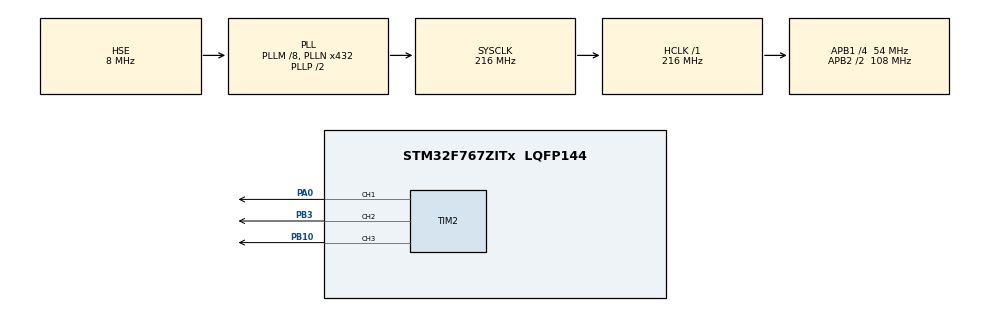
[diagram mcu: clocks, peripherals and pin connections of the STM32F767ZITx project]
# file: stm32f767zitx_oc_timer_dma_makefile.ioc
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Dma.Request0=TIM2_CH1
Dma.Request1=TIM2_CH2/CH4
Dma.Request2=TIM2_UP/CH3
Dma.TIM2_CH1.0.Direction=DMA_MEMORY_TO_PERIPH
Dma.TIM2_CH1.0.FIFOMode=DMA_FIFOMODE_ENABLE
Dma.TIM2_CH1.0.FIFOThreshold=DMA_FIFO_THRESHOLD_FULL
Dma.TIM2_CH1.0.Instance=DMA1_Stream5
Dma.TIM2_CH1.0.MemBurst=DMA_MBURST_SINGLE
Dma.TIM2_CH1.0.MemDataAlignment=DMA_MDATAALIGN_WORD
Dma.TIM2_CH1.0.MemInc=DMA_MINC_ENABLE
Dma.TIM2_CH1.0.Mode=DMA_CIRCULAR
Dma.TIM2_CH1.0.PeriphBurst=DMA_PBURST_SINGLE
Dma.TIM2_CH1.0.PeriphDataAlignment=DMA_PDATAALIGN_WORD
Dma.TIM2_CH1.0.PeriphInc=DMA_PINC_DISABLE
Dma.TIM2_CH1.0.Priority=DMA_PRIORITY_HIGH
Dma.TIM2_CH2/CH4.1.Direction=DMA_MEMORY_TO_PERIPH
Dma.TIM2_CH2/CH4.1.FIFOMode=DMA_FIFOMODE_ENABLE
Dma.TIM2_CH2/CH4.1.FIFOThreshold=DMA_FIFO_THRESHOLD_FULL
Dma.TIM2_CH2/CH4.1.Instance=DMA1_Stream6
Dma.TIM2_CH2/CH4.1.MemBurst=DMA_MBURST_SINGLE
Dma.TIM2_CH2/CH4.1.MemDataAlignment=DMA_MDATAALIGN_WORD
Dma.TIM2_CH2/CH4.1.MemInc=DMA_MINC_ENABLE
Dma.TIM2_CH2/CH4.1.Mode=DMA_CIRCULAR
Dma.TIM2_CH2/CH4.1.PeriphBurst=DMA_PBURST_SINGLE
Dma.TIM2_CH2/CH4.1.PeriphDataAlignment=DMA_PDATAALIGN_WORD
Dma.TIM2_CH2/CH4.1.PeriphInc=DMA_PINC_DISABLE
Dma.TIM2_CH2/CH4.1.Priority=DMA_PRIORITY_MEDIUM
Dma.TIM2_UP/CH3.2.Direction=DMA_MEMORY_TO_PERIPH
Dma.TIM2_UP/CH3.2.FIFOMode=DMA_FIFOMODE_ENABLE
Dma.TIM2_UP/CH3.2.FIFOThreshold=DMA_FIFO_THRESHOLD_FULL
Dma.TIM2_UP/CH3.2.Instance=DMA1_Stream1
Dma.TIM2_UP/CH3.2.MemBurst=DMA_MBURST_SINGLE
Dma.TIM2_UP/CH3.2.MemDataAlignment=DMA_MDATAALIGN_WORD
Dma.TIM2_UP/CH3.2.MemInc=DMA_MINC_ENABLE
Dma.TIM2_UP/CH3.2.Mode=DMA_CIRCULAR
Dma.TIM2_UP/CH3.2.PeriphBurst=DMA_PBURST_SINGLE
Dma.TIM2_UP/CH3.2.PeriphDataAlignment=DMA_PDATAALIGN_WORD
Dma.TIM2_UP/CH3.2.PeriphInc=DMA_PINC_DISABLE
Dma.TIM2_UP/CH3.2.Priority=DMA_PRIORITY_LOW
Mcu.Family=STM32F7
Mcu.Name=STM32F767ZITx
Mcu.Package=LQFP144
NVIC.DMA1_Stream1_IRQn=true\:0\:0\:false\:false\:true\:false\:true\:true
NVIC.DMA1_Stream5_IRQn=true\:0\:0\:false\:false\:true\:false\:true\:true
NVIC.DMA1_Stream6_IRQn=true\:0\:0\:false\:false\:true\:false\:true\:true
NVIC.PriorityGroup=NVIC_PRIORITYGROUP_4
PA0/WKUP.Signal=S_TIM2_CH1_ETR
PB10.Signal=S_TIM2_CH3
PB3.Signal=S_TIM2_CH2
PH0/OSC_IN.Mode=HSE-External-Clock-Source
PH0/OSC_IN.Signal=RCC_OSC_IN
PH1/OSC_OUT.Mode=HSE-External-Clock-Source
PH1/OSC_OUT.Signal=RCC_OSC_OUT
ProjectManager.HeapSize=0x200
ProjectManager.StackSize=0x400
ProjectManager.TargetToolchain=Makefile
RCC.48MHZClocksFreq_Value=24000000
RCC.AHBFreq_Value=216000000
RCC.APB1CLKDivider=RCC_HCLK_DIV4
RCC.APB1Freq_Value=54000000
RCC.APB1TimFreq_Value=108000000
RCC.APB2CLKDivider=RCC_HCLK_DIV2
RCC.APB2Freq_Value=108000000
RCC.APB2TimFreq_Value=216000000
RCC.CortexFreq_Value=216000000
RCC.HCLKFreq_Value=216000000
RCC.HSE_VALUE=8000000
RCC.HSI_VALUE=16000000
RCC.LSE_VALUE=32768
RCC.PLLM=8
RCC.PLLMUL=RCC_PLL_MUL9
RCC.PLLN=432
RCC.PLLSourceVirtual=RCC_PLLSOURCE_HSE
RCC.PRESCALERUSB=RCC_USBCLKSOURCE_PLL_DIV1_5
RCC.SYSCLKFreq_VALUE=216000000
RCC.SYSCLKSource=RCC_SYSCLKSOURCE_PLLCLK
RCC.SYSCLKSourceVirtual=RCC_SYSCLKSOURCE_PLLCLK
RCC.USBFreq_Value=216000000
RCC.VCOOutputFreq_Value=432000000
SH.S_TIM2_CH1_ETR.0=TIM2_CH1,Output Compare1 CH1
SH.S_TIM2_CH2.0=TIM2_CH2,Output Compare2 CH2
SH.S_TIM2_CH3.0=TIM2_CH3,Output Compare3 CH3
TIM2.Channel-Output\ Compare1\ CH1=TIM_CHANNEL_1
TIM2.Channel-Output\ Compare2\ CH2=TIM_CHANNEL_2
TIM2.Channel-Output\ Compare3\ CH3=TIM_CHANNEL_3
TIM2.OC1Preload=DISABLE
TIM2.OCMode_1=TIM_OCMODE_TOGGLE
TIM2.OCMode_2=TIM_OCMODE_TOGGLE
TIM2.OCMode_3=TIM_OCMODE_TOGGLE
VP_TIM2_VS_ClockSourceINT.Mode=Internal
board=NUCLEO-F767ZI

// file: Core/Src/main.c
/* USER CODE BEGIN Header */
/**
 ******************************************************************************
 * @file           : main.c
 * @brief          : Main program body
 ******************************************************************************
 * @attention
 *
 * Copyright (c) 2023 STMicroelectronics.
 * All rights reserved.
 *
 * This software is licensed under terms that can be found in the LICENSE file
 * in the root directory of this software component.
 * If no LICENSE file comes with this software, it is provided AS-IS.
 *
 ******************************************************************************
 */
/* USER CODE END Header */
#include "main.h"

/* USER CODE BEGIN PD */
#define BUFFER_LEN 32
/* USER CODE END PD */

TIM_HandleTypeDef htim2;
DMA_HandleTypeDef hdma_tim2_ch1;
DMA_HandleTypeDef hdma_tim2_ch2_ch4;
DMA_HandleTypeDef hdma_tim2_up_ch3;

/* USER CODE BEGIN PV */
const uint16_t CH1_FREQ = 270; // 135 for 400kHz; 270 for 200kHz
uint32_t pMem0DataCh1[BUFFER_LEN];
uint32_t pMem1DataCh1[BUFFER_LEN];
uint32_t pMem0DataCh2[BUFFER_LEN];
uint32_t pMem1DataCh2[BUFFER_LEN];
uint32_t pMem0DataCh3[BUFFER_LEN];
uint32_t pMem1DataCh3[BUFFER_LEN];

/* USER CODE END PV */

void SystemClock_Config(void);
static void MX_GPIO_Init(void);
static void MX_DMA_Init(void);
static void MX_TIM2_Init(void);
/* USER CODE BEGIN PFP */
void UpdateBuffer(uint32_t *buffer, uint32_t start_index, uint32_t start_value, uint32_t increment, size_t length);

/* USER CODE END PFP */

int main(void)
{

  /* MCU Configuration--------------------------------------------------------*/

  /* Reset of all peripherals, Initializes the Flash interface and the Systick. */
  HAL_Init();

  /* Configure the system clock */
  SystemClock_Config();

  /* Initialize all configured peripherals */
  MX_GPIO_Init();
  MX_DMA_Init();
  MX_TIM2_Init();
  /* USER CODE BEGIN 2 */
  UpdateBuffer(pMem0DataCh1, 0, CH1_FREQ, CH1_FREQ, BUFFER_LEN);
  UpdateBuffer(pMem1DataCh1, 0, pMem0DataCh1[BUFFER_LEN - 1] + CH1_FREQ, CH1_FREQ, BUFFER_LEN);
  UpdateBuffer(pMem0DataCh2, 0, CH1_FREQ, CH1_FREQ, BUFFER_LEN);
  UpdateBuffer(pMem1DataCh2, 0, pMem0DataCh2[BUFFER_LEN - 1] + CH1_FREQ, CH1_FREQ, BUFFER_LEN);
  UpdateBuffer(pMem0DataCh3, 0, CH1_FREQ, CH1_FREQ, BUFFER_LEN);
  UpdateBuffer(pMem1DataCh3, 0, pMem0DataCh2[BUFFER_LEN - 1] + CH1_FREQ, CH1_FREQ, BUFFER_LEN);

  TIM_OC_Start_DMA_Double_Buffer(&htim2, TIM_CHANNEL_1, (uint32_t)pMem0DataCh1, (uint32_t)&htim2.Instance->CCR1, (uint32_t)pMem1DataCh1, BUFFER_LEN);
  TIM_OC_Start_DMA_Double_Buffer(&htim2, TIM_CHANNEL_2, (uint32_t)pMem0DataCh2, (uint32_t)&htim2.Instance->CCR2, (uint32_t)pMem1DataCh2, BUFFER_LEN);
  TIM_OC_Start_DMA_Double_Buffer(&htim2, TIM_CHANNEL_3, (uint32_t)pMem0DataCh2, (uint32_t)&htim2.Instance->CCR3, (uint32_t)pMem1DataCh3, BUFFER_LEN);

  // Reset Counter, CNT, as 0
  __HAL_TIM_SET_COUNTER(&htim2, 0);

  /* USER CODE END 2 */

  /* Infinite loop */
  while (1)
  {

  }
}

void SystemClock_Config(void)
{
  RCC_OscInitTypeDef RCC_OscInitStruct = {0};
  RCC_ClkInitTypeDef RCC_ClkInitStruct = {0};

  /** Configure the main internal regulator output voltage
   */
  __HAL_RCC_PWR_CLK_ENABLE();
  __HAL_PWR_VOLTAGESCALING_CONFIG(PWR_REGULATOR_VOLTAGE_SCALE1);

  /** Initializes the RCC Oscillators according to the specified parameters
   * in the RCC_OscInitTypeDef structure.
   */
  RCC_OscInitStruct.OscillatorType = RCC_OSCILLATORTYPE_HSE;
  RCC_OscInitStruct.HSEState = RCC_HSE_BYPASS;
  RCC_OscInitStruct.PLL.PLLState = RCC_PLL_ON;
  RCC_OscInitStruct.PLL.PLLSource = RCC_PLLSOURCE_HSE;
  RCC_OscInitStruct.PLL.PLLM = 8;
  RCC_OscInitStruct.PLL.PLLN = 432;
  RCC_OscInitStruct.PLL.PLLP = RCC_PLLP_DIV2;
  RCC_OscInitStruct.PLL.PLLQ = 2;
  RCC_OscInitStruct.PLL.PLLR = 2;
  if (HAL_RCC_OscConfig(&RCC_OscInitStruct) != HAL_OK)
  {
    Error_Handler();
  }

  /** Activate the Over-Drive mode
   */
  if (HAL_PWREx_EnableOverDrive() != HAL_OK)
  {
    Error_Handler();
  }

  /** Initializes the CPU, AHB and APB buses clocks
   */
  RCC_ClkInitStruct.ClockType = RCC_CLOCKTYPE_HCLK | RCC_CLOCKTYPE_SYSCLK | RCC_CLOCKTYPE_PCLK1 | RCC_CLOCKTYPE_PCLK2;
  RCC_ClkInitStruct.SYSCLKSource = RCC_SYSCLKSOURCE_PLLCLK;
  RCC_ClkInitStruct.AHBCLKDivider = RCC_SYSCLK_DIV1;
  RCC_ClkInitStruct.APB1CLKDivider = RCC_HCLK_DIV4;
  RCC_ClkInitStruct.APB2CLKDivider = RCC_HCLK_DIV2;

  if (HAL_RCC_ClockConfig(&RCC_ClkInitStruct, FLASH_LATENCY_7) != HAL_OK)
  {
    Error_Handler();
  }
}

static void MX_TIM2_Init(void)
{

  TIM_ClockConfigTypeDef sClockSourceConfig = {0};
  TIM_MasterConfigTypeDef sMasterConfig = {0};
  TIM_OC_InitTypeDef sConfigOC = {0};

  htim2.Instance = TIM2;
  htim2.Init.Prescaler = 0;
  htim2.Init.CounterMode = TIM_COUNTERMODE_UP;
  htim2.Init.Period = 4294967295;
  htim2.Init.ClockDivision = TIM_CLOCKDIVISION_DIV1;
  htim2.Init.AutoReloadPreload = TIM_AUTORELOAD_PRELOAD_DISABLE;
  if (HAL_TIM_Base_Init(&htim2) != HAL_OK)
  {
    Error_Handler();
  }
  sClockSourceConfig.ClockSource = TIM_CLOCKSOURCE_INTERNAL;
  if (HAL_TIM_ConfigClockSource(&htim2, &sClockSourceConfig) != HAL_OK)
  {
    Error_Handler();
  }
  if (HAL_TIM_OC_Init(&htim2) != HAL_OK)
  {
    Error_Handler();
  }
  sMasterConfig.MasterOutputTrigger = TIM_TRGO_RESET;
  sMasterConfig.MasterSlaveMode = TIM_MASTERSLAVEMODE_DISABLE;
  if (HAL_TIMEx_MasterConfigSynchronization(&htim2, &sMasterConfig) != HAL_OK)
  {
    Error_Handler();
  }
  sConfigOC.OCMode = TIM_OCMODE_TOGGLE;
  sConfigOC.Pulse = 0;
  sConfigOC.OCPolarity = TIM_OCPOLARITY_HIGH;
  sConfigOC.OCFastMode = TIM_OCFAST_DISABLE;
  if (HAL_TIM_OC_ConfigChannel(&htim2, &sConfigOC, TIM_CHANNEL_1) != HAL_OK)
  {
    Error_Handler();
  }
  if (HAL_TIM_OC_ConfigChannel(&htim2, &sConfigOC, TIM_CHANNEL_2) != HAL_OK)
  {
    Error_Handler();
  }
  if (HAL_TIM_OC_ConfigChannel(&htim2, &sConfigOC, TIM_CHANNEL_3) != HAL_OK)
  {
    Error_Handler();
  }
  HAL_TIM_MspPostInit(&htim2);
}

static void MX_DMA_Init(void)
{

  /* DMA controller clock enable */
  __HAL_RCC_DMA1_CLK_ENABLE();

  /* DMA interrupt init */
  /* DMA1_Stream1_IRQn interrupt configuration */
  HAL_NVIC_SetPriority(DMA1_Stream1_IRQn, 0, 0);
  HAL_NVIC_EnableIRQ(DMA1_Stream1_IRQn);
  /* DMA1_Stream5_IRQn interrupt configuration */
  HAL_NVIC_SetPriority(DMA1_Stream5_IRQn, 0, 0);
  HAL_NVIC_EnableIRQ(DMA1_Stream5_IRQn);
  /* DMA1_Stream6_IRQn interrupt configuration */
  HAL_NVIC_SetPriority(DMA1_Stream6_IRQn, 0, 0);
  HAL_NVIC_EnableIRQ(DMA1_Stream6_IRQn);
}

static void MX_GPIO_Init(void)
{

  /* GPIO Ports Clock Enable */
  __HAL_RCC_GPIOH_CLK_ENABLE();
  __HAL_RCC_GPIOA_CLK_ENABLE();
  __HAL_RCC_GPIOB_CLK_ENABLE();

}

/* USER CODE BEGIN 4 */

/**
 * @brief This function is executed in case of the DMA M0 buffer transfer complete event occurrence.
 */
void PingPongM0TransferCompleteCallback(TIM_HandleTypeDef *htim)
{
  if (htim->Channel == HAL_TIM_ACTIVE_CHANNEL_1)
  {
    /* Current memory buffer used is Memory 1 */
    UpdateBuffer(pMem0DataCh1, 0, pMem1DataCh1[BUFFER_LEN - 1] + CH1_FREQ, CH1_FREQ, BUFFER_LEN);
  }
  else if (htim->Channel == HAL_TIM_ACTIVE_CHANNEL_2)
  {
    /* Current memory buffer used is Memory 1 */
    UpdateBuffer(pMem0DataCh2, 0, pMem1DataCh2[BUFFER_LEN - 1] + CH1_FREQ, CH1_FREQ, BUFFER_LEN);
  }
  else if (htim->Channel == HAL_TIM_ACTIVE_CHANNEL_3)
  {
    /* Current memory buffer used is Memory 1 */
    UpdateBuffer(pMem0DataCh3, 0, pMem1DataCh3[BUFFER_LEN - 1] + CH1_FREQ, CH1_FREQ, BUFFER_LEN);
  }
}

/**
 * @brief This function is executed in case of the DMA M1 buffer transfer complete event occurrence.
 */
void PingPongM1TransferCompleteCallback(TIM_HandleTypeDef *htim)
{
  if (htim->Channel == HAL_TIM_ACTIVE_CHANNEL_1)
  {
    /* Current memory buffer used is Memory 0 */
    UpdateBuffer(pMem1DataCh1, 0, pMem0DataCh1[BUFFER_LEN - 1] + CH1_FREQ, CH1_FREQ, BUFFER_LEN);
  }
  else if (htim->Channel == HAL_TIM_ACTIVE_CHANNEL_2)
  {
    /* Current memory buffer used is Memory 0 */
    UpdateBuffer(pMem1DataCh2, 0, pMem0DataCh2[BUFFER_LEN - 1] + CH1_FREQ, CH1_FREQ, BUFFER_LEN);
  }
  else if (htim->Channel == HAL_TIM_ACTIVE_CHANNEL_3)
  {
    /* Current memory buffer used is Memory 0 */
    UpdateBuffer(pMem1DataCh3, 0, pMem0DataCh3[BUFFER_LEN - 1] + CH1_FREQ, CH1_FREQ, BUFFER_LEN);
  }
}

void HAL_TIM_PWM_PulseFinishedHalfCpltCallback(TIM_HandleTypeDef *htim)
{
  if (htim->Channel == HAL_TIM_ACTIVE_CHANNEL_1)
  {
    /* Current memory buffer used is Memory 0 */
    if ((htim->hdma[TIM_DMA_ID_CC1]->Instance->CR & DMA_SxCR_CT) == RESET)
    {
      UpdateBuffer(pMem1DataCh1, 0, pMem0DataCh1[BUFFER_LEN - 1] + CH1_FREQ, CH1_FREQ, BUFFER_LEN);
    }
    /* Current memory buffer used is Memory 1 */
    else
    {
      UpdateBuffer(pMem0DataCh1, 0, pMem1DataCh1[BUFFER_LEN - 1] + CH1_FREQ, CH1_FREQ, BUFFER_LEN);
    }
  }
  else if (htim->Channel == HAL_TIM_ACTIVE_CHANNEL_2)
  {
    /* Current memory buffer used is Memory 0 */
    if ((htim->hdma[TIM_DMA_ID_CC2]->Instance->CR & DMA_SxCR_CT) == RESET)
    {
      UpdateBuffer(pMem1DataCh2, 0, pMem0DataCh2[BUFFER_LEN - 1] + CH1_FREQ, CH1_FREQ, BUFFER_LEN);
    }
    /* Current memory buffer used is Memory 1 */
    else
    {
      UpdateBuffer(pMem0DataCh2, 0, pMem1DataCh2[BUFFER_LEN - 1] + CH1_FREQ, CH1_FREQ, BUFFER_LEN);
    }
  }
  else if (htim->Channel == HAL_TIM_ACTIVE_CHANNEL_3)
  {
    /* Current memory buffer used is Memory 0 */
    if ((htim->hdma[TIM_DMA_ID_CC1]->Instance->CR & DMA_SxCR_CT) == RESET)
    {
      UpdateBuffer(pMem1DataCh3, 0, pMem0DataCh3[BUFFER_LEN - 1] + CH1_FREQ, CH1_FREQ, BUFFER_LEN);
    }
    /* Current memory buffer used is Memory 1 */
    else
    {
      UpdateBuffer(pMem0DataCh3, 0, pMem1DataCh3[BUFFER_LEN - 1] + CH1_FREQ, CH1_FREQ, BUFFER_LEN);
    }
  }
}

void UpdateBuffer(uint32_t *buffer, uint32_t start_index, uint32_t start_value, uint32_t increment, size_t length)
{
  for (uint32_t i = start_index; i < (start_index + length); i++)
  {
    buffer[i] = start_value + increment * (i - start_index);
  }
}

/* USER CODE END 4 */

void Error_Handler(void)
{
  __disable_irq();
  while (1)
  {
  }
}
